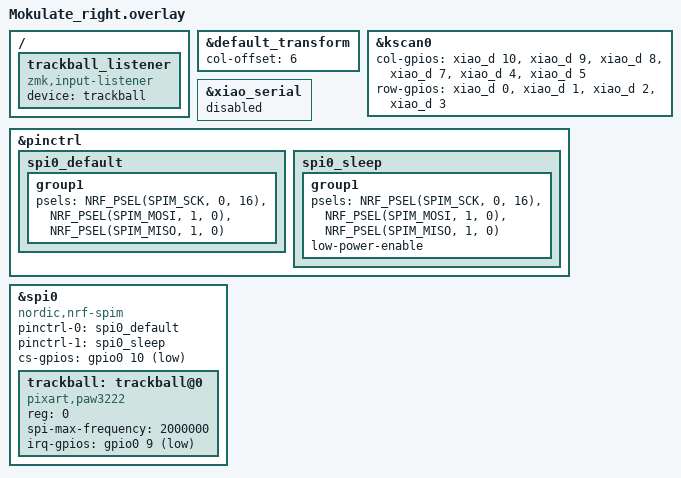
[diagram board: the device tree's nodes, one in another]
#include "Mokulate.dtsi"

&default_transform {
    col-offset = <6>;
};

&kscan0 {
    col-gpios
        = <&xiao_d 10 GPIO_ACTIVE_HIGH>  /* Col0 */
        , <&xiao_d 9 GPIO_ACTIVE_HIGH>   /* Col1 */
        , <&xiao_d 8 GPIO_ACTIVE_HIGH>   /* Col2 */
        , <&xiao_d 7 GPIO_ACTIVE_HIGH>   /* Col3 */
        , <&xiao_d 4 GPIO_ACTIVE_HIGH>   /* Col4 */
        , <&xiao_d 5 GPIO_ACTIVE_HIGH>   /* Col5 */
        ;
    row-gpios
        = <&xiao_d 0 (GPIO_ACTIVE_HIGH | GPIO_PULL_DOWN)>  /* Row0 */
        , <&xiao_d 1 (GPIO_ACTIVE_HIGH | GPIO_PULL_DOWN)>  /* Row1 */
        , <&xiao_d 2 (GPIO_ACTIVE_HIGH | GPIO_PULL_DOWN)>  /* Row2 */
        , <&xiao_d 3 (GPIO_ACTIVE_HIGH | GPIO_PULL_DOWN)>  /* Row3 */
        ;
};

&xiao_serial { status = "disabled"; };

// PAW3222 Trackball Configuration
// Wiring: CS=P0.10, MOTION=P0.09, SDIO=P1.00, SCLK=P0.16

&pinctrl {
    spi0_default: spi0_default {
        group1 {
            psels = <NRF_PSEL(SPIM_SCK, 0, 16)>,   // SCLK = P0.16
                    <NRF_PSEL(SPIM_MOSI, 1, 0)>,   // SDIO = P1.00
                    <NRF_PSEL(SPIM_MISO, 1, 0)>;   // SDIO = P1.00 (same as MOSI)
        };
    };

    spi0_sleep: spi0_sleep {
        group1 {
            psels = <NRF_PSEL(SPIM_SCK, 0, 16)>,
                    <NRF_PSEL(SPIM_MOSI, 1, 0)>,
                    <NRF_PSEL(SPIM_MISO, 1, 0)>;
            low-power-enable;
        };
    };
};

&spi0 {
    status = "okay";
    compatible = "nordic,nrf-spim";
    pinctrl-0 = <&spi0_default>;
    pinctrl-1 = <&spi0_sleep>;
    pinctrl-names = "default", "sleep";
    cs-gpios = <&gpio0 10 GPIO_ACTIVE_LOW>;  // CS = P0.10

    trackball: trackball@0 {
        status = "okay";
        compatible = "pixart,paw3222";
        reg = <0>;
        spi-max-frequency = <2000000>;
        irq-gpios = <&gpio0 9 (GPIO_ACTIVE_LOW | GPIO_PULL_UP)>;  // MOTION = P0.09
    };
};

// Trackball input listener (central side - direct processing)
/ {
    trackball_listener: trackball_listener {
        compatible = "zmk,input-listener";
        device = <&trackball>;
        status = "okay";
    };
};
